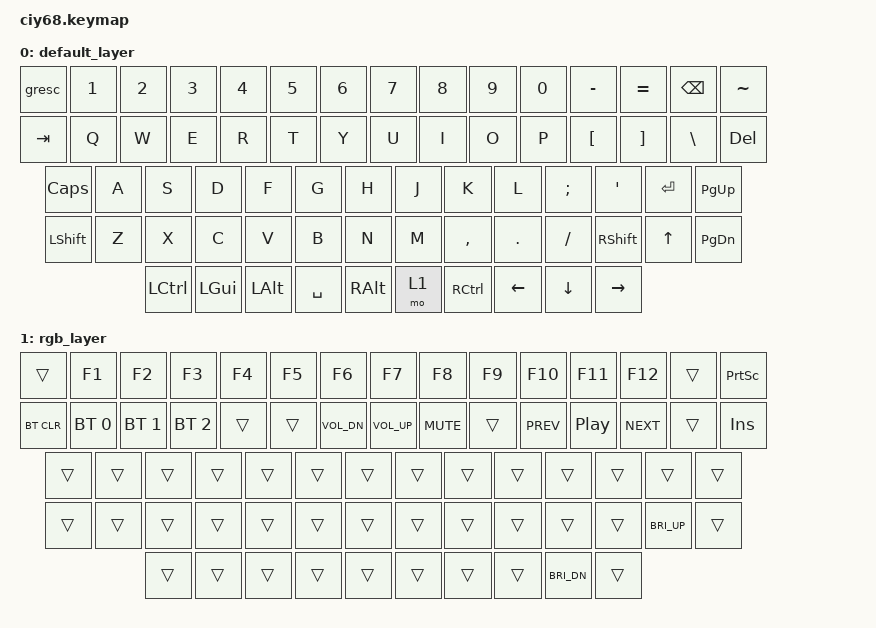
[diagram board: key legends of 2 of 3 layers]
// This file was generated from a template. Edit it to match your keyboard.
// See https://zmk.dev/docs/development/hardware-integration/new-shield for more instructions.

#include <behaviors.dtsi>
#include <dt-bindings/zmk/keys.h>
#include <dt-bindings/zmk/bt.h>

/ {
    // Define a default keymap here.
    // See https://zmk.dev/docs/development/hardware-integration/new-shield#default-keymap.
    keymap {
        compatible = "zmk,keymap";

        default_layer {
// --------------------------------------------------------------------------------------------------
// | ESC |  1  |  2  |  3  |  4  |  5  |  6  |  7  |  8  |  9  |  0  |  -  |  =  |   BSPC   | TILDE |
// | TAB  |  Q  |  W  |  E  |  R  |  T  |  Y  |  U  |  I  |  O  |  P  |  [  |  ]  |   "|"   |  DEL  |
// | CAPS  |  A  |  S  |  D  |  F  |  G  |  H  |  J  |  K  |  L  |  ;  |  '  |     ENTER    |PAGE_UP|
// |  SHIFT  |  Z  |  X  |  C  |  V  |  B  |  N  |  M  |  ,  |  .  |  /  |   SHIFT   |  UP  |PAGE_DN|
// | CTL | WIN | ALT |               SPACE                | ALT | MO(1) | CTL | LEFT | DOWN | RIGHT |
// --------------------------------------------------------------------------------------------------
            bindings = <
    &gresc  &kp N1 &kp N2 &kp N3 &kp N4 &kp N5 &kp N6 &kp N7 &kp N8 &kp N9 &kp N0 &kp MINUS &kp EQUAL  &kp BSPC  &kp TILDE
    &kp TAB  &kp Q  &kp W  &kp E  &kp R  &kp T  &kp Y  &kp U  &kp I  &kp O  &kp P  &kp LBKT  &kp RBKT  &kp BSLH  &kp DEL
    &kp CLCK  &kp A  &kp S  &kp D  &kp F  &kp G  &kp H  &kp J  &kp K  &kp L  &kp SEMI &kp SQT     &kp RET        &kp PG_UP
    &kp LSHFT   &kp Z  &kp X  &kp C  &kp V  &kp B  &kp N  &kp M  &kp COMMA &kp DOT &kp FSLH  &kp RSHFT  &kp UP   &kp PG_DN
    &kp LCTRL &kp LGUI &kp LALT            &kp SPACE             &kp RALT  &mo 1  &kp RCTRL  &kp LEFT   &kp DOWN &kp RIGHT
            >;
        };

        rgb_layer {
// ----------------------------------------------------------------------------------------------------------
// | BT CLR | F1  | F2  | F3  | F4  | F5  | F6  | F7  | F8  | F9  | F10  | F11 | F12 |            | PRT SCR |
// |  BT 1   |   |     |   |       |      |        |      |   |     |    |     |     |            |   INS   |
// |   BT 2   |    |      |    |       |       |       |       |   |     |   |     |              |
// |    BT 3     |     |      |      |     |     |     |     |     |     |     |                  |
// |   BT 4  |      |      |                                    |         |       |       |       |
// ----------------------------------------------------------------------------------------------------------
            bindings = <
    &trans   &kp F1 &kp F2  &kp F3  &kp F4  &kp F5  &kp F6  &kp F7  &kp F8  &kp F9  &kp F10 &kp F11 &kp F12         &trans  &kp PSCRN
    &bt BT_CLR &bt BT_SEL 0 &bt BT_SEL 1 &bt BT_SEL 2  &trans  &trans  &kp C_VOL_DN  &kp C_VOL_UP &kp C_MUTE  &trans  &kp C_PREV &kp C_PLAY_PAUSE &kp C_NEXT      &trans  &kp INS
    &trans   &trans    &trans  &trans  &trans  &trans  &trans  &trans  &trans  &trans  &trans  &trans  &trans     &trans 
    &trans     &trans    &trans  &trans  &trans  &trans   &trans  &trans  &trans   &trans   &trans    &trans &kp C_BRI_UP      &trans 
    &trans  &trans   &trans                            &trans                     &trans  &trans  &trans  &trans &kp C_BRI_DN  &trans 
            >;
        };

        idk_layer {
// ----------------------------------------------------------------------------------------------------------
// |        | F1  | F2  | F3  | F4  | F5  | F6  | F7  | F8  | F9  | F10  | F11 | F12 |            | PRT SCR |
// |         |   |     |   |       |      |        |      |   |     |    |     |     |            |   INS   |
// |          |    |      |    |       |       |       |       |   |     |   |     |              |
// |             |     |      |      |     |     |     |     |     |     |     |                  |
// |         |      |      |                                    |         |       |       |       |
// ----------------------------------------------------------------------------------------------------------
            bindings = <
    &trans &kp KP_N1 &kp KP_N2 &kp KP_N3 &kp KP_N4 &kp KP_N5 &kp KP_N6 &kp KP_N7 &kp KP_N8 &kp KP_N9 &kp KP_N0 &trans  &trans  &trans  &trans
    &trans    &trans    &trans   &trans   &trans   &trans   &trans   &trans      &trans      &trans   &trans   &trans   &trans  &trans  &trans
    &trans     &trans    &trans   &trans   &trans   &trans   &trans   &trans   &trans   &trans   &trans   &trans  &trans        &trans  &trans
    &trans       &trans    &trans   &trans   &trans   &trans   &trans   &trans   &trans    &trans    &trans     &trans          &trans  &trans
    &trans    &trans   &trans                            &trans                     &trans  &trans  &trans  &trans              &trans  &trans
            >;
        };
    };

//    macros {
//        BT0: bt0 {
//            compatible = "zmk,behavior-macro";
//            #binding-cells = <0>;
//            wait-ms = <30>;
//        tap-ms = <40>;
//            bindings
//                = <&macro_press &kp LSHFT>
//                , <&macro_tap &kp Z &kp M &kp K>
//                , <&macro_release &kp LSHFT>
//                ;
//        };
//        BT1: bt1 {
//            compatible = "zmk,behavior-macro";
//            #binding-cells = <0>;
//            wait-ms = <30>;
//            tap-ms = <40>;
//            bindings
//                = <&macro_press &kp LSHFT>
//                , <&macro_tap &kp Z &kp M &kp K>
//                , <&macro_release &kp LSHFT>
//                ;
//        };
//        BT2: bt2 {
//            compatible = "zmk,behavior-macro";
//            #binding-cells = <0>;
//            wait-ms = <30>;
//            tap-ms = <40>;
//            bindings
//                = <&macro_press &kp LSHFT>
//                , <&macro_tap &kp Z &kp M &kp K>
//                , <&macro_release &kp LSHFT>
//                ;
//        };
//    };
};
